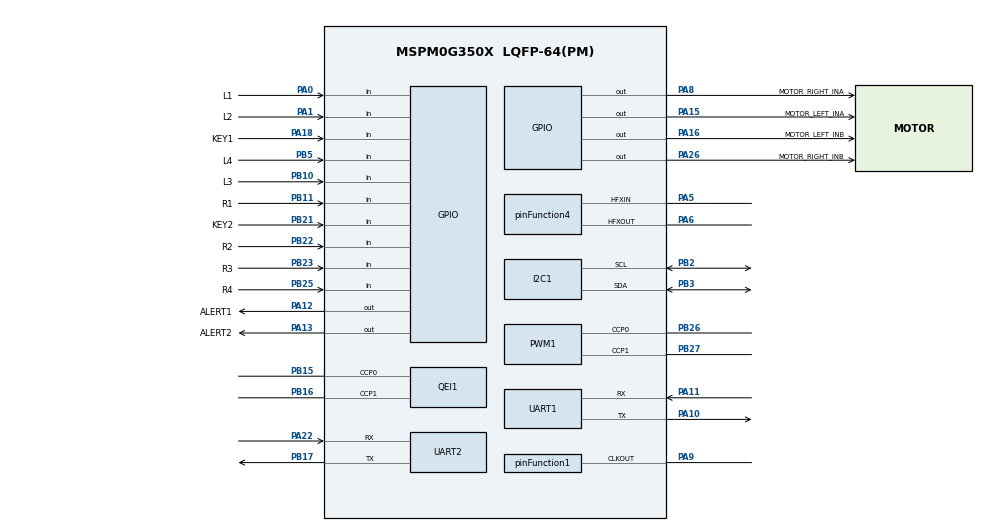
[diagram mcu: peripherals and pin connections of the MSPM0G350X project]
/**
 * @cliArgs --device "MSPM0G350X" --package "LQFP-64(PM)" --part "Default" --product "mspm0_sdk@2.01.00.03"
 * @versions {"tool":"1.19.0+3426"}
 */

/**
 * Import the modules used in this configuration.
 */
const GPIO   = scripting.addModule("/ti/driverlib/GPIO", {}, false);
const GPIO1  = GPIO.addInstance();
const I2C    = scripting.addModule("/ti/driverlib/I2C", {}, false);
const I2C1   = I2C.addInstance();
const PWM    = scripting.addModule("/ti/driverlib/PWM", {}, false);
const PWM1   = PWM.addInstance();
const QEI    = scripting.addModule("/ti/driverlib/QEI", {}, false);
const QEI1   = QEI.addInstance();
const SYSCTL = scripting.addModule("/ti/driverlib/SYSCTL");
const TIMER  = scripting.addModule("/ti/driverlib/TIMER", {}, false);
const TIMER1 = TIMER.addInstance();
const TIMER2 = TIMER.addInstance();
const UART   = scripting.addModule("/ti/driverlib/UART", {}, false);
const UART1  = UART.addInstance();
const UART2  = UART.addInstance();

/**
 * Write custom configuration values to the imported modules.
 */
const divider1       = system.clockTree["EXCLKDIV"];
divider1.divideValue = 10;

const divider2       = system.clockTree["HFCLK4MFPCLKDIV"];
divider2.divideValue = 10;

const divider9       = system.clockTree["UDIV"];
divider9.divideValue = 2;

const gate7  = system.clockTree["MFCLKGATE"];
gate7.enable = true;

const gate8  = system.clockTree["MFPCLKGATE"];
gate8.enable = true;

const mux3       = system.clockTree["EXCLKMUX"];
mux3.inputSelect = "EXCLKMUX_ULPCLK";

const mux4       = system.clockTree["EXHFMUX"];
mux4.inputSelect = "EXHFMUX_XTAL";

const mux5       = system.clockTree["EXLFMUX"];
mux5.inputSelect = "EXLFMUX_XTAL";

const mux8       = system.clockTree["HSCLKMUX"];
mux8.inputSelect = "HSCLKMUX_SYSPLL2X";

const mux12       = system.clockTree["SYSPLLMUX"];
mux12.inputSelect = "zSYSPLLMUX_HFCLK";

const pinFunction1                        = system.clockTree["CLKOUT"];
pinFunction1.ClkOutForceHighDrive         = true;
pinFunction1.enable                       = true;
pinFunction1.peripheral.$assign           = "SYSCTL";
pinFunction1.peripheral.clkOutPin.$assign = "PA9";

const pinFunction3     = system.clockTree["HFCLKEXT"];
pinFunction3.inputFreq = 40;

const pinFunction4                        = system.clockTree["HFXT"];
pinFunction4.inputFreq                    = 40;
pinFunction4.enable                       = true;
pinFunction4.HFXTStartup                  = 50;
pinFunction4.peripheral.$assign           = "SYSCTL";
pinFunction4.peripheral.hfxInPin.$assign  = "PA5";
pinFunction4.peripheral.hfxOutPin.$assign = "PA6";

const pinFunction6              = system.clockTree["LFXT"];
pinFunction6.inputFreq          = 32.768;
pinFunction6.LFCLKDriveStrength = "LOWEST";

GPIO1.$name                               = "GPIO_GRP_0";
GPIO1.associatedPins.create(16);
GPIO1.associatedPins[0].$name             = "MOTOR_LEFT_INA";
GPIO1.associatedPins[0].assignedPort      = "PORTA";
GPIO1.associatedPins[0].ioStructure       = "SD";
GPIO1.associatedPins[0].pin.$assign       = "PA15";
GPIO1.associatedPins[1].$name             = "MOTOR_LEFT_INB";
GPIO1.associatedPins[1].assignedPort      = "PORTA";
GPIO1.associatedPins[1].ioStructure       = "SD";
GPIO1.associatedPins[1].pin.$assign       = "PA16";
GPIO1.associatedPins[2].$name             = "MOTOR_RIGHT_INA";
GPIO1.associatedPins[2].assignedPort      = "PORTA";
GPIO1.associatedPins[2].ioStructure       = "SD";
GPIO1.associatedPins[2].pin.$assign       = "PA8";
GPIO1.associatedPins[3].$name             = "MOTOR_RIGHT_INB";
GPIO1.associatedPins[3].ioStructure       = "SD";
GPIO1.associatedPins[3].assignedPort      = "PORTA";
GPIO1.associatedPins[3].pin.$assign       = "PA26";
GPIO1.associatedPins[4].assignedPort      = "PORTA";
GPIO1.associatedPins[4].$name             = "ALERT1";
GPIO1.associatedPins[4].pin.$assign       = "PA12";
GPIO1.associatedPins[5].$name             = "ALERT2";
GPIO1.associatedPins[5].pin.$assign       = "PA13";
GPIO1.associatedPins[6].direction         = "INPUT";
GPIO1.associatedPins[6].$name             = "KEY1";
GPIO1.associatedPins[6].internalResistor  = "PULL_DOWN";
GPIO1.associatedPins[6].interruptPriority = "2";
GPIO1.associatedPins[6].polarity          = "RISE";
GPIO1.associatedPins[6].pin.$assign       = "PA18";
GPIO1.associatedPins[7].$name             = "KEY2";
GPIO1.associatedPins[7].direction         = "INPUT";
GPIO1.associatedPins[7].internalResistor  = "PULL_UP";
GPIO1.associatedPins[7].pin.$assign       = "PB21";
GPIO1.associatedPins[8].$name             = "R4";
GPIO1.associatedPins[8].direction         = "INPUT";
GPIO1.associatedPins[8].inputFilter       = "8_CYCLES";
GPIO1.associatedPins[8].pin.$assign       = "PB25";
GPIO1.associatedPins[9].$name             = "R3";
GPIO1.associatedPins[9].direction         = "INPUT";
GPIO1.associatedPins[9].inputFilter       = "8_CYCLES";
GPIO1.associatedPins[9].pin.$assign       = "PB23";
GPIO1.associatedPins[10].direction        = "INPUT";
GPIO1.associatedPins[10].inputFilter      = "8_CYCLES";
GPIO1.associatedPins[10].$name            = "R2";
GPIO1.associatedPins[10].pin.$assign      = "PB22";
GPIO1.associatedPins[11].$name            = "R1";
GPIO1.associatedPins[11].direction        = "INPUT";
GPIO1.associatedPins[11].inputFilter      = "8_CYCLES";
GPIO1.associatedPins[11].pin.$assign      = "PB11";
GPIO1.associatedPins[12].$name            = "L4";
GPIO1.associatedPins[12].direction        = "INPUT";
GPIO1.associatedPins[12].inputFilter      = "8_CYCLES";
GPIO1.associatedPins[12].pin.$assign      = "PB5";
GPIO1.associatedPins[13].$name            = "L3";
GPIO1.associatedPins[13].direction        = "INPUT";
GPIO1.associatedPins[13].inputFilter      = "8_CYCLES";
GPIO1.associatedPins[13].pin.$assign      = "PB10";
GPIO1.associatedPins[14].direction        = "INPUT";
GPIO1.associatedPins[14].inputFilter      = "8_CYCLES";
GPIO1.associatedPins[14].$name            = "L2";
GPIO1.associatedPins[14].pin.$assign      = "PA1";
GPIO1.associatedPins[15].$name            = "L1";
GPIO1.associatedPins[15].direction        = "INPUT";
GPIO1.associatedPins[15].inputFilter      = "8_CYCLES";
GPIO1.associatedPins[15].pin.$assign      = "PA0";

const Board = scripting.addModule("/ti/driverlib/Board", {}, false);

I2C1.basicEnableController             = true;
I2C1.basicControllerStandardBusSpeed   = "Fast";
I2C1.$name                             = "OLED_I2C";
I2C1.peripheral.$assign                = "I2C1";
I2C1.peripheral.sdaPin.$assign         = "PB3";
I2C1.peripheral.sclPin.$assign         = "PB2";
I2C1.sdaPinConfig.$name                = "ti_driverlib_gpio_GPIOPinGeneric0";
I2C1.sdaPinConfig.hideOutputInversion  = scripting.forceWrite(false);
I2C1.sdaPinConfig.onlyInternalResistor = scripting.forceWrite(false);
I2C1.sdaPinConfig.passedPeripheralType = scripting.forceWrite("Digital");
I2C1.sdaPinConfig.enableConfig         = true;
I2C1.sdaPinConfig.internalResistor     = "PULL_UP";
I2C1.sclPinConfig.$name                = "ti_driverlib_gpio_GPIOPinGeneric1";
I2C1.sclPinConfig.hideOutputInversion  = scripting.forceWrite(false);
I2C1.sclPinConfig.onlyInternalResistor = scripting.forceWrite(false);
I2C1.sclPinConfig.passedPeripheralType = scripting.forceWrite("Digital");
I2C1.sclPinConfig.enableConfig         = true;
I2C1.sclPinConfig.internalResistor     = "PULL_UP";

PWM1.$name                              = "MOTOR_PWM";
PWM1.pwmMode                            = "EDGE_ALIGN_UP";
PWM1.clockPrescale                      = 4;
PWM1.enableShadowLoad                   = true;
PWM1.timerStartTimer                    = true;
PWM1.peripheral.$assign                 = "TIMA1";
PWM1.peripheral.ccp0Pin.$assign         = "PB26";
PWM1.peripheral.ccp1Pin.$assign         = "PB27";
PWM1.PWM_CHANNEL_0.$name                = "ti_driverlib_pwm_PWMTimerCC0";
PWM1.PWM_CHANNEL_0.dutyCycle            = 50;
PWM1.PWM_CHANNEL_1.$name                = "ti_driverlib_pwm_PWMTimerCC1";
PWM1.PWM_CHANNEL_1.dutyCycle            = 50;
PWM1.ccp0PinConfig.$name                = "ti_driverlib_gpio_GPIOPinGeneric4";
PWM1.ccp0PinConfig.direction            = scripting.forceWrite("OUTPUT");
PWM1.ccp0PinConfig.hideOutputInversion  = scripting.forceWrite(false);
PWM1.ccp0PinConfig.onlyInternalResistor = scripting.forceWrite(false);
PWM1.ccp0PinConfig.passedPeripheralType = scripting.forceWrite("Digital");
PWM1.ccp1PinConfig.$name                = "ti_driverlib_gpio_GPIOPinGeneric5";
PWM1.ccp1PinConfig.direction            = scripting.forceWrite("OUTPUT");
PWM1.ccp1PinConfig.hideOutputInversion  = scripting.forceWrite(false);
PWM1.ccp1PinConfig.onlyInternalResistor = scripting.forceWrite(false);
PWM1.ccp1PinConfig.passedPeripheralType = scripting.forceWrite("Digital");

QEI1.$name                              = "MUX_QEI";
QEI1.timerStartTimer                    = true;
QEI1.clockSource                        = "MFCLK";
QEI1.peripheral.ccp0Pin.$assign         = "PB15";
QEI1.peripheral.ccp1Pin.$assign         = "PB16";
QEI1.ccp0PinConfig.$name                = "ti_driverlib_gpio_GPIOPinGeneric6";
QEI1.ccp0PinConfig.hideOutputInversion  = scripting.forceWrite(false);
QEI1.ccp0PinConfig.onlyInternalResistor = scripting.forceWrite(false);
QEI1.ccp0PinConfig.passedPeripheralType = scripting.forceWrite("Digital");
QEI1.ccp1PinConfig.$name                = "ti_driverlib_gpio_GPIOPinGeneric7";
QEI1.ccp1PinConfig.hideOutputInversion  = scripting.forceWrite(false);
QEI1.ccp1PinConfig.onlyInternalResistor = scripting.forceWrite(false);
QEI1.ccp1PinConfig.passedPeripheralType = scripting.forceWrite("Digital");

SYSCTL.forceDefaultClkConfig = true;
SYSCTL.MFCLKEn               = true;
SYSCTL.clockTreeEn           = true;

TIMER1.timerMode          = "PERIODIC";
TIMER1.interrupts         = ["ZERO"];
TIMER1.timerClkPrescale   = 100;
TIMER1.timerClkDiv        = 4;
TIMER1.timerClkSrc        = "MFCLK";
TIMER1.timerPeriod        = "10 ms";
TIMER1.timerStartTimer    = true;
TIMER1.$name              = "TICKER_TIMER";
TIMER1.interruptPriority  = "2";
TIMER1.peripheral.$assign = "TIMA0";

TIMER2.$name = "TIMER_0";

UART1.targetBaudRate                   = 115200;
UART1.enabledInterrupts                = ["RX"];
UART1.interruptPriority                = "2";
UART1.uartClkDiv                       = "5";
UART1.$name                            = "DEBUG_UART";
UART1.peripheral.rxPin.$assign         = "PA11";
UART1.peripheral.txPin.$assign         = "PA10";
UART1.txPinConfig.direction            = scripting.forceWrite("OUTPUT");
UART1.txPinConfig.hideOutputInversion  = scripting.forceWrite(false);
UART1.txPinConfig.onlyInternalResistor = scripting.forceWrite(false);
UART1.txPinConfig.passedPeripheralType = scripting.forceWrite("Digital");
UART1.txPinConfig.$name                = "ti_driverlib_gpio_GPIOPinGeneric2";
UART1.rxPinConfig.hideOutputInversion  = scripting.forceWrite(false);
UART1.rxPinConfig.onlyInternalResistor = scripting.forceWrite(false);
UART1.rxPinConfig.passedPeripheralType = scripting.forceWrite("Digital");
UART1.rxPinConfig.$name                = "ti_driverlib_gpio_GPIOPinGeneric3";

UART2.$name                            = "GY62_UART";
UART2.targetBaudRate                   = 115200;
UART2.enabledInterrupts                = ["RX"];
UART2.interruptPriority                = "2";
UART2.peripheral.$assign               = "UART2";
UART2.peripheral.rxPin.$assign         = "PA22";
UART2.peripheral.txPin.$assign         = "PB17";
UART2.txPinConfig.direction            = scripting.forceWrite("OUTPUT");
UART2.txPinConfig.hideOutputInversion  = scripting.forceWrite(false);
UART2.txPinConfig.onlyInternalResistor = scripting.forceWrite(false);
UART2.txPinConfig.passedPeripheralType = scripting.forceWrite("Digital");
UART2.txPinConfig.$name                = "ti_driverlib_gpio_GPIOPinGeneric8";
UART2.rxPinConfig.hideOutputInversion  = scripting.forceWrite(false);
UART2.rxPinConfig.onlyInternalResistor = scripting.forceWrite(false);
UART2.rxPinConfig.passedPeripheralType = scripting.forceWrite("Digital");
UART2.rxPinConfig.$name                = "ti_driverlib_gpio_GPIOPinGeneric9";
UART2.rxPinConfig.internalResistor     = "PULL_DOWN";

/**
 * Pinmux solution for unlocked pins/peripherals. This ensures that minor changes to the automatic solver in a future
 * version of the tool will not impact the pinmux you originally saw.  These lines can be completely deleted in order to
 * re-solve from scratch.
 */
Board.peripheral.$suggestSolution          = "DEBUGSS";
Board.peripheral.swclkPin.$suggestSolution = "PA20";
Board.peripheral.swdioPin.$suggestSolution = "PA19";
QEI1.peripheral.$suggestSolution           = "TIMG8";
TIMER2.peripheral.$suggestSolution         = "TIMG0";
UART1.peripheral.$suggestSolution          = "UART0";
